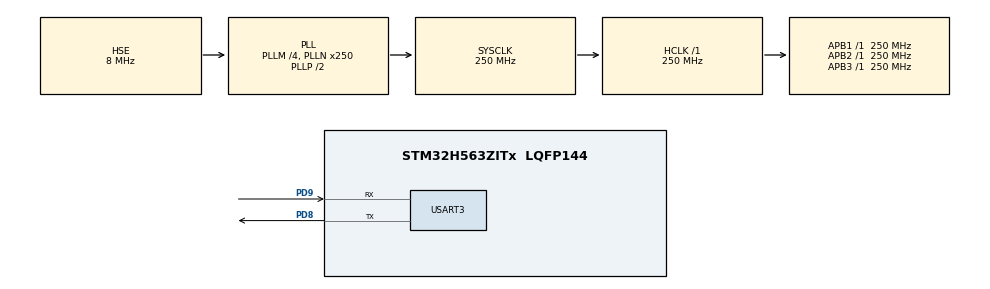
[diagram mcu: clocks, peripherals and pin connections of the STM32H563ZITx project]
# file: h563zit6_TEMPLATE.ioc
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BOOTPATH.BootPathName=LEGACY
BOOTPATH.UserSelectedBootPath=LEGACY
CORTEX_M33_NS.userName=CORTEX_M33
Mcu.Family=STM32H5
Mcu.Name=STM32H563ZITx
Mcu.Package=LQFP144
NVIC.PriorityGroup=NVIC_PRIORITYGROUP_4
NVIC.USART3_IRQn=true\:0\:0\:false\:false\:true\:true\:true\:true
PC14-OSC32_IN(OSC32_IN).Mode=LSE-External-Oscillator
PC14-OSC32_IN(OSC32_IN).Signal=RCC_OSC32_IN
PC15-OSC32_OUT(OSC32_OUT).Mode=LSE-External-Oscillator
PC15-OSC32_OUT(OSC32_OUT).Signal=RCC_OSC32_OUT
PD8.Mode=Asynchronous
PD8.Signal=USART3_TX
PD9.Mode=Asynchronous
PD9.Signal=USART3_RX
PH0-OSC_IN(PH0).Mode=HSE-External-Oscillator
PH0-OSC_IN(PH0).Signal=RCC_OSC_IN
PH1-OSC_OUT(PH1).Mode=HSE-External-Oscillator
PH1-OSC_OUT(PH1).Signal=RCC_OSC_OUT
ProjectManager.HeapSize=0x2000
ProjectManager.StackSize=0x4000
ProjectManager.TargetToolchain=STM32CubeIDE
RCC.ADCFreq_Value=250000000
RCC.AHBFreq_Value=250000000
RCC.APB1Freq_Value=250000000
RCC.APB1TimFreq_Value=250000000
RCC.APB2Freq_Value=250000000
RCC.APB2TimFreq_Value=250000000
RCC.APB3Freq_Value=250000000
RCC.CSI_VALUE=4000000
RCC.CortexFreq_Value=250000000
RCC.EPOD_VALUE=8000000
RCC.HCLKFreq_Value=250000000
RCC.HSE_VALUE=8000000
RCC.HSI48_VALUE=48000000
RCC.HSI_VALUE=64000000
RCC.LSIRC_VALUE=32000
RCC.PLLM=4
RCC.PLLN=250
RCC.PLLSourceVirtual=RCC_PLL1_SOURCE_HSE
RCC.SYSCLKFreq_VALUE=250000000
RCC.SYSCLKSource=RCC_SYSCLKSOURCE_PLLCLK
RCC.USBFreq_Value=48000000
RCC.VCOOutputFreq_Value=500000000
USART3.VirtualMode-Asynchronous=VM_ASYNC
VP_BOOTPATH_VS_BOOTPATH.Mode=BP_Activate
VP_CORTEX_M33_NS_VS_Hclk.Mode=Hclk_Mode
VP_ICACHE_VS_ICACHE.Mode=DefaultMode
VP_MEMORYMAP_VS_MEMORYMAP.Mode=CurAppReg
VP_PWR_VS_DBSignals.Mode=DisableDeadBatterySignals
VP_PWR_VS_LPOM.Mode=PowerOptimisation
VP_PWR_VS_SECSignals.Mode=Security/Privilege
board=custom

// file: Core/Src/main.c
/* USER CODE BEGIN Header */
/**
  ******************************************************************************
  * @file           : main.c
  * @brief          : Main program body
  ******************************************************************************
  * @attention
  *
  * Copyright (c) 2024 STMicroelectronics.
  * All rights reserved.
  *
  * This software is licensed under terms that can be found in the LICENSE file
  * in the root directory of this software component.
  * If no LICENSE file comes with this software, it is provided AS-IS.
  *
  ******************************************************************************
  */
/* USER CODE END Header */
#include "main.h"
#include "icache.h"
#include "memorymap.h"
#include "usart.h"
#include "gpio.h"

/* USER CODE BEGIN Includes */
#include "sys_command_line.h"
/* USER CODE END Includes */

void SystemClock_Config(void);

int main(void)
{

  /* MCU Configuration--------------------------------------------------------*/

  /* Reset of all peripherals, Initializes the Flash interface and the Systick. */
  HAL_Init();

  /* Configure the system clock */
  SystemClock_Config();

  /* Initialize all configured peripherals */
  MX_GPIO_Init();
  MX_ICACHE_Init();
  MX_USART3_UART_Init();
  /* USER CODE BEGIN 2 */
  CLI_INIT(&huart3, USART3_IRQn);
  /* USER CODE END 2 */

  /* Infinite loop */
  /* USER CODE BEGIN WHILE */
  while (1)
  {
	CLI_RUN();
    /* USER CODE END WHILE */

  }
}

void SystemClock_Config(void)
{
  RCC_OscInitTypeDef RCC_OscInitStruct = {0};
  RCC_ClkInitTypeDef RCC_ClkInitStruct = {0};

  /** Configure the main internal regulator output voltage
  */
  __HAL_PWR_VOLTAGESCALING_CONFIG(PWR_REGULATOR_VOLTAGE_SCALE0);

  while(!__HAL_PWR_GET_FLAG(PWR_FLAG_VOSRDY)) {}

  /** Initializes the RCC Oscillators according to the specified parameters
  * in the RCC_OscInitTypeDef structure.
  */
  RCC_OscInitStruct.OscillatorType = RCC_OSCILLATORTYPE_HSE;
  RCC_OscInitStruct.HSEState = RCC_HSE_ON;
  RCC_OscInitStruct.PLL.PLLState = RCC_PLL_ON;
  RCC_OscInitStruct.PLL.PLLSource = RCC_PLL1_SOURCE_HSE;
  RCC_OscInitStruct.PLL.PLLM = 4;
  RCC_OscInitStruct.PLL.PLLN = 250;
  RCC_OscInitStruct.PLL.PLLP = 2;
  RCC_OscInitStruct.PLL.PLLQ = 2;
  RCC_OscInitStruct.PLL.PLLR = 2;
  RCC_OscInitStruct.PLL.PLLRGE = RCC_PLL1_VCIRANGE_1;
  RCC_OscInitStruct.PLL.PLLVCOSEL = RCC_PLL1_VCORANGE_WIDE;
  RCC_OscInitStruct.PLL.PLLFRACN = 0;
  if (HAL_RCC_OscConfig(&RCC_OscInitStruct) != HAL_OK)
  {
    Error_Handler();
  }

  /** Initializes the CPU, AHB and APB buses clocks
  */
  RCC_ClkInitStruct.ClockType = RCC_CLOCKTYPE_HCLK|RCC_CLOCKTYPE_SYSCLK
                              |RCC_CLOCKTYPE_PCLK1|RCC_CLOCKTYPE_PCLK2
                              |RCC_CLOCKTYPE_PCLK3;
  RCC_ClkInitStruct.SYSCLKSource = RCC_SYSCLKSOURCE_PLLCLK;
  RCC_ClkInitStruct.AHBCLKDivider = RCC_SYSCLK_DIV1;
  RCC_ClkInitStruct.APB1CLKDivider = RCC_HCLK_DIV1;
  RCC_ClkInitStruct.APB2CLKDivider = RCC_HCLK_DIV1;
  RCC_ClkInitStruct.APB3CLKDivider = RCC_HCLK_DIV1;

  if (HAL_RCC_ClockConfig(&RCC_ClkInitStruct, FLASH_LATENCY_5) != HAL_OK)
  {
    Error_Handler();
  }

  /** Configure the programming delay
  */
  __HAL_FLASH_SET_PROGRAM_DELAY(FLASH_PROGRAMMING_DELAY_2);
}

void Error_Handler(void)
{
  __disable_irq();
  while (1)
  {
  }
}
